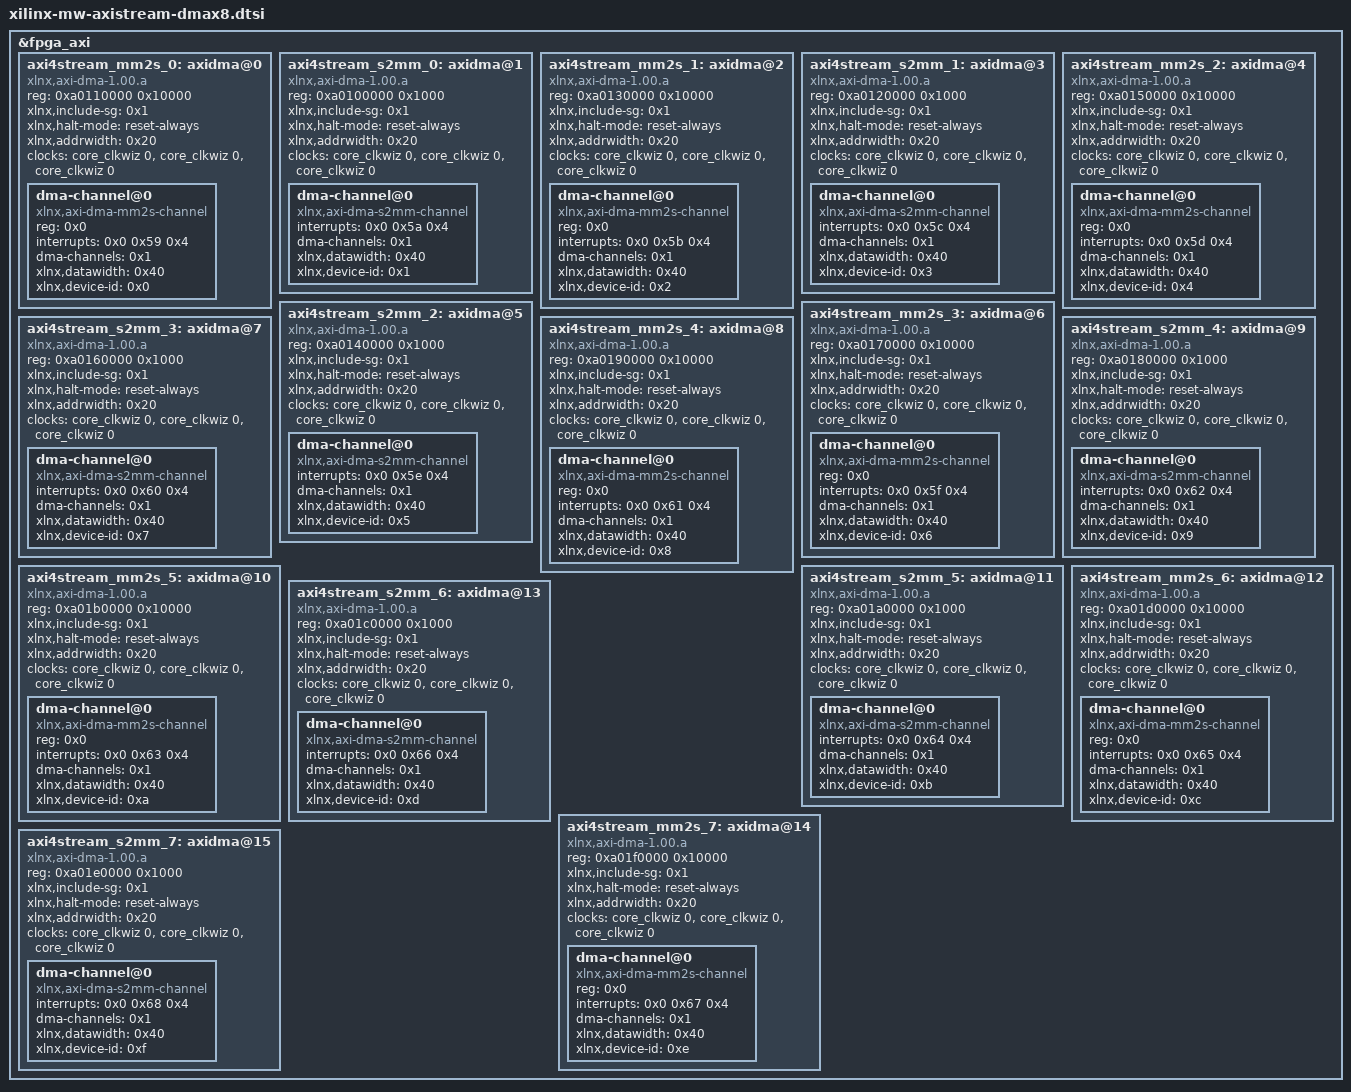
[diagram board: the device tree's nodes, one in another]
&fpga_axi {
	axi4stream_mm2s_0:axidma@0 {
		#dma-cells = <0x1>;
		#address-cells = <1>;
		#size-cells = <0>;
		compatible = "xlnx,axi-dma-1.00.a";
		reg = <0xa0110000 0x10000>;
		xlnx,include-sg = <0x1>;
		xlnx,halt-mode = "reset-always";
		xlnx,addrwidth = <0x20>;
		clocks = <&core_clkwiz 0>, <&core_clkwiz 0>, <&core_clkwiz 0>;
		clock-names = "s_axi_lite_aclk", "m_axi_sg_aclk", "m_axi_mm2s_aclk";
		dma-channel@0  {
			reg = <0x0>;
			compatible = "xlnx,axi-dma-mm2s-channel";
			interrupts = <0x0 0x59 0x4>;
			dma-channels = <0x1>;
			xlnx,datawidth = <0x40>;
			xlnx,device-id = <0x0>;
		};
	};
	axi4stream_s2mm_0:axidma@1 {
		#dma-cells = <0x1>;
		#address-cells = <1>;
		#size-cells = <0>;
		compatible = "xlnx,axi-dma-1.00.a";
		reg = <0xa0100000 0x1000>;
		xlnx,include-sg = <0x1>;
		xlnx,halt-mode = "reset-always";
		xlnx,addrwidth = <0x20>;
		clocks = <&core_clkwiz 0>, <&core_clkwiz 0>, <&core_clkwiz 0>;
		clock-names = "s_axi_lite_aclk", "m_axi_sg_aclk", "m_axi_s2mm_aclk";
		dma-channel@0 {
			compatible = "xlnx,axi-dma-s2mm-channel";
			interrupts = <0x0 0x5a 0x4>;
			dma-channels = <0x1>;			
			xlnx,datawidth = <0x40>;
			xlnx,device-id = <0x1>;
		};
	};
	axi4stream_mm2s_1:axidma@2 {
		#dma-cells = <0x1>;
		#address-cells = <1>;
		#size-cells = <0>;
		compatible = "xlnx,axi-dma-1.00.a";
		reg = <0xa0130000 0x10000>;
		xlnx,include-sg = <0x1>;
		xlnx,halt-mode = "reset-always";
		xlnx,addrwidth = <0x20>;
		clocks = <&core_clkwiz 0>, <&core_clkwiz 0>, <&core_clkwiz 0>;
		clock-names = "s_axi_lite_aclk", "m_axi_sg_aclk", "m_axi_mm2s_aclk";
		dma-channel@0  {
			reg = <0x0>;
			compatible = "xlnx,axi-dma-mm2s-channel";
			interrupts = <0x0 0x5b 0x4>;
			dma-channels = <0x1>;
			xlnx,datawidth = <0x40>;
			xlnx,device-id = <0x2>;
		};
	};
	axi4stream_s2mm_1:axidma@3 {
		#dma-cells = <0x1>;
		#address-cells = <1>;
		#size-cells = <0>;
		compatible = "xlnx,axi-dma-1.00.a";
		reg = <0xa0120000 0x1000>;
		xlnx,include-sg = <0x1>;
		xlnx,halt-mode = "reset-always";
		xlnx,addrwidth = <0x20>;
		clocks = <&core_clkwiz 0>, <&core_clkwiz 0>, <&core_clkwiz 0>;
		clock-names = "s_axi_lite_aclk", "m_axi_sg_aclk", "m_axi_s2mm_aclk";
		dma-channel@0 {
			compatible = "xlnx,axi-dma-s2mm-channel";
			interrupts = <0x0 0x5c 0x4>;
			dma-channels = <0x1>;			
			xlnx,datawidth = <0x40>;
			xlnx,device-id = <0x3>;
		};
	};
	axi4stream_mm2s_2:axidma@4 {
		#dma-cells = <0x1>;
		#address-cells = <1>;
		#size-cells = <0>;
		compatible = "xlnx,axi-dma-1.00.a";
		reg = <0xa0150000 0x10000>;
		xlnx,include-sg = <0x1>;
		xlnx,halt-mode = "reset-always";
		xlnx,addrwidth = <0x20>;
		clocks = <&core_clkwiz 0>, <&core_clkwiz 0>, <&core_clkwiz 0>;
		clock-names = "s_axi_lite_aclk", "m_axi_sg_aclk", "m_axi_mm2s_aclk";
		dma-channel@0  {
			reg = <0x0>;
			compatible = "xlnx,axi-dma-mm2s-channel";
			interrupts = <0x0 0x5d 0x4>;
			dma-channels = <0x1>;
			xlnx,datawidth = <0x40>;
			xlnx,device-id = <0x4>;
		};
	};
	axi4stream_s2mm_2:axidma@5 {
		#dma-cells = <0x1>;
		#address-cells = <1>;
		#size-cells = <0>;
		compatible = "xlnx,axi-dma-1.00.a";
		reg = <0xa0140000 0x1000>;
		xlnx,include-sg = <0x1>;
		xlnx,halt-mode = "reset-always";
		xlnx,addrwidth = <0x20>;
		clocks = <&core_clkwiz 0>, <&core_clkwiz 0>, <&core_clkwiz 0>;
		clock-names = "s_axi_lite_aclk", "m_axi_sg_aclk", "m_axi_s2mm_aclk";
		dma-channel@0 {
			compatible = "xlnx,axi-dma-s2mm-channel";
			interrupts = <0x0 0x5e 0x4>;
			dma-channels = <0x1>;			
			xlnx,datawidth = <0x40>;
			xlnx,device-id = <0x5>;
		};
	};
	axi4stream_mm2s_3:axidma@6 {
		#dma-cells = <0x1>;
		#address-cells = <1>;
		#size-cells = <0>;
		compatible = "xlnx,axi-dma-1.00.a";
		reg = <0xa0170000 0x10000>;
		xlnx,include-sg = <0x1>;
		xlnx,halt-mode = "reset-always";
		xlnx,addrwidth = <0x20>;
		clocks = <&core_clkwiz 0>, <&core_clkwiz 0>, <&core_clkwiz 0>;
		clock-names = "s_axi_lite_aclk", "m_axi_sg_aclk", "m_axi_mm2s_aclk";
		dma-channel@0  {
			reg = <0x0>;
			compatible = "xlnx,axi-dma-mm2s-channel";
			interrupts = <0x0 0x5f 0x4>;
			dma-channels = <0x1>;
			xlnx,datawidth = <0x40>;
			xlnx,device-id = <0x6>;
		};
	};
	axi4stream_s2mm_3:axidma@7 {
		#dma-cells = <0x1>;
		#address-cells = <1>;
		#size-cells = <0>;
		compatible = "xlnx,axi-dma-1.00.a";
		reg = <0xa0160000 0x1000>;
		xlnx,include-sg = <0x1>;
		xlnx,halt-mode = "reset-always";
		xlnx,addrwidth = <0x20>;
		clocks = <&core_clkwiz 0>, <&core_clkwiz 0>, <&core_clkwiz 0>;
		clock-names = "s_axi_lite_aclk", "m_axi_sg_aclk", "m_axi_s2mm_aclk";
		dma-channel@0 {
			compatible = "xlnx,axi-dma-s2mm-channel";
			interrupts = <0x0 0x60 0x4>;
			dma-channels = <0x1>;			
			xlnx,datawidth = <0x40>;
			xlnx,device-id = <0x7>;
		};
	};
	axi4stream_mm2s_4:axidma@8 {
		#dma-cells = <0x1>;
		#address-cells = <1>;
		#size-cells = <0>;
		compatible = "xlnx,axi-dma-1.00.a";
		reg = <0xa0190000 0x10000>;
		xlnx,include-sg = <0x1>;
		xlnx,halt-mode = "reset-always";
		xlnx,addrwidth = <0x20>;
		clocks = <&core_clkwiz 0>, <&core_clkwiz 0>, <&core_clkwiz 0>;
		clock-names = "s_axi_lite_aclk", "m_axi_sg_aclk", "m_axi_mm2s_aclk";
		dma-channel@0  {
			reg = <0x0>;
			compatible = "xlnx,axi-dma-mm2s-channel";
			interrupts = <0x0 0x61 0x4>;
			dma-channels = <0x1>;
			xlnx,datawidth = <0x40>;
			xlnx,device-id = <0x8>;
		};
	};
	axi4stream_s2mm_4:axidma@9 {
		#dma-cells = <0x1>;
		#address-cells = <1>;
		#size-cells = <0>;
		compatible = "xlnx,axi-dma-1.00.a";
		reg = <0xa0180000 0x1000>;
		xlnx,include-sg = <0x1>;
		xlnx,halt-mode = "reset-always";
		xlnx,addrwidth = <0x20>;
		clocks = <&core_clkwiz 0>, <&core_clkwiz 0>, <&core_clkwiz 0>;
		clock-names = "s_axi_lite_aclk", "m_axi_sg_aclk", "m_axi_s2mm_aclk";
		dma-channel@0 {
			compatible = "xlnx,axi-dma-s2mm-channel";
			interrupts = <0x0 0x62 0x4>;
			dma-channels = <0x1>;			
			xlnx,datawidth = <0x40>;
			xlnx,device-id = <0x9>;
		};
	};
	axi4stream_mm2s_5:axidma@10 {
		#dma-cells = <0x1>;
		#address-cells = <1>;
		#size-cells = <0>;
		compatible = "xlnx,axi-dma-1.00.a";
		reg = <0xa01b0000 0x10000>;
		xlnx,include-sg = <0x1>;
		xlnx,halt-mode = "reset-always";
		xlnx,addrwidth = <0x20>;
		clocks = <&core_clkwiz 0>, <&core_clkwiz 0>, <&core_clkwiz 0>;
		clock-names = "s_axi_lite_aclk", "m_axi_sg_aclk", "m_axi_mm2s_aclk";
		dma-channel@0  {
			reg = <0x0>;
			compatible = "xlnx,axi-dma-mm2s-channel";
			interrupts = <0x0 0x63 0x4>;
			dma-channels = <0x1>;
			xlnx,datawidth = <0x40>;
			xlnx,device-id = <0xa>;
		};
	};
	axi4stream_s2mm_5:axidma@11 {
		#dma-cells = <0x1>;
		#address-cells = <1>;
		#size-cells = <0>;
		compatible = "xlnx,axi-dma-1.00.a";
		reg = <0xa01a0000 0x1000>;
		xlnx,include-sg = <0x1>;
		xlnx,halt-mode = "reset-always";
		xlnx,addrwidth = <0x20>;
		clocks = <&core_clkwiz 0>, <&core_clkwiz 0>, <&core_clkwiz 0>;
		clock-names = "s_axi_lite_aclk", "m_axi_sg_aclk", "m_axi_s2mm_aclk";
		dma-channel@0 {
			compatible = "xlnx,axi-dma-s2mm-channel";
			interrupts = <0x0 0x64 0x4>;
			dma-channels = <0x1>;			
			xlnx,datawidth = <0x40>;
			xlnx,device-id = <0xb>;
		};
	};
	axi4stream_mm2s_6:axidma@12 {
		#dma-cells = <0x1>;
		#address-cells = <1>;
		#size-cells = <0>;
		compatible = "xlnx,axi-dma-1.00.a";
		reg = <0xa01d0000 0x10000>;
		xlnx,include-sg = <0x1>;
		xlnx,halt-mode = "reset-always";
		xlnx,addrwidth = <0x20>;
		clocks = <&core_clkwiz 0>, <&core_clkwiz 0>, <&core_clkwiz 0>;
		clock-names = "s_axi_lite_aclk", "m_axi_sg_aclk", "m_axi_mm2s_aclk";
		dma-channel@0  {
			reg = <0x0>;
			compatible = "xlnx,axi-dma-mm2s-channel";
			interrupts = <0x0 0x65 0x4>;
			dma-channels = <0x1>;
			xlnx,datawidth = <0x40>;
			xlnx,device-id = <0xc>;
		};
	};
	axi4stream_s2mm_6:axidma@13 {
		#dma-cells = <0x1>;
		#address-cells = <1>;
		#size-cells = <0>;
		compatible = "xlnx,axi-dma-1.00.a";
		reg = <0xa01c0000 0x1000>;
		xlnx,include-sg = <0x1>;
		xlnx,halt-mode = "reset-always";
		xlnx,addrwidth = <0x20>;
		clocks = <&core_clkwiz 0>, <&core_clkwiz 0>, <&core_clkwiz 0>;
		clock-names = "s_axi_lite_aclk", "m_axi_sg_aclk", "m_axi_s2mm_aclk";
		dma-channel@0 {
			compatible = "xlnx,axi-dma-s2mm-channel";
			interrupts = <0x0 0x66 0x4>;
			dma-channels = <0x1>;			
			xlnx,datawidth = <0x40>;
			xlnx,device-id = <0xd>;
		};
	};
	axi4stream_mm2s_7:axidma@14 {
		#dma-cells = <0x1>;
		#address-cells = <1>;
		#size-cells = <0>;
		compatible = "xlnx,axi-dma-1.00.a";
		reg = <0xa01f0000 0x10000>;
		xlnx,include-sg = <0x1>;
		xlnx,halt-mode = "reset-always";
		xlnx,addrwidth = <0x20>;
		clocks = <&core_clkwiz 0>, <&core_clkwiz 0>, <&core_clkwiz 0>;
		clock-names = "s_axi_lite_aclk", "m_axi_sg_aclk", "m_axi_mm2s_aclk";
		dma-channel@0  {
			reg = <0x0>;
			compatible = "xlnx,axi-dma-mm2s-channel";
			interrupts = <0x0 0x67 0x4>;
			dma-channels = <0x1>;
			xlnx,datawidth = <0x40>;
			xlnx,device-id = <0xe>;
		};
	};
	axi4stream_s2mm_7:axidma@15 {
		#dma-cells = <0x1>;
		#address-cells = <1>;
		#size-cells = <0>;
		compatible = "xlnx,axi-dma-1.00.a";
		reg = <0xa01e0000 0x1000>;
		xlnx,include-sg = <0x1>;
		xlnx,halt-mode = "reset-always";
		xlnx,addrwidth = <0x20>;
		clocks = <&core_clkwiz 0>, <&core_clkwiz 0>, <&core_clkwiz 0>;
		clock-names = "s_axi_lite_aclk", "m_axi_sg_aclk", "m_axi_s2mm_aclk";
		dma-channel@0 {
			compatible = "xlnx,axi-dma-s2mm-channel";
			interrupts = <0x0 0x68 0x4>;
			dma-channels = <0x1>;			
			xlnx,datawidth = <0x40>;
			xlnx,device-id = <0xf>;
		};
	};
};

